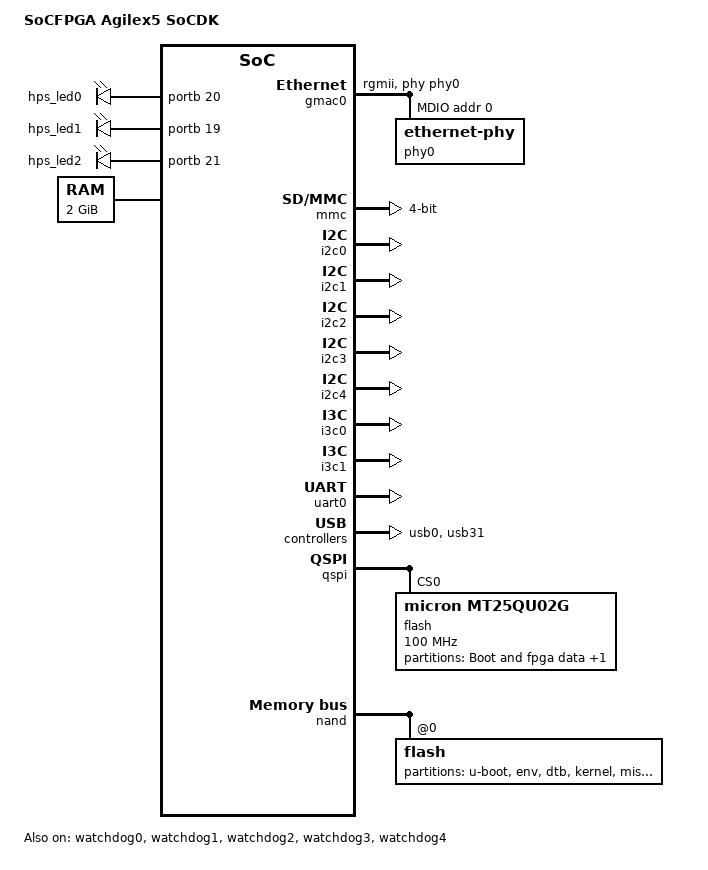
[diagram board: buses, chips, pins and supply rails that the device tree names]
// SPDX-License-Identifier:     GPL-2.0
/*
 * Copyright (C) 2023, Intel Corporation
 */
#include "socfpga_agilex5.dtsi"

/ {
	model = "SoCFPGA Agilex5 SoCDK";
	compatible = "intel,socfpga-agilex5-socdk", "intel,socfpga-agilex";

	aliases {
		serial0 = &uart0;
		ethernet0 = &gmac0;
	};

	chosen {
		stdout-path = "serial0:115200n8";
		bootargs = "console=uart8250,mmio32,0x10c02000,115200n8 \
			root=/dev/ram0 rw initrd=0x10000000 init=/sbin/init \
			ramdisk_size=10000000 earlycon=uart8250,mmio32,0x10c02000,115200n8 \
			panic=-1 nosmp rootfstype=ext3";
	};

	leds {
		compatible = "gpio-leds";
		hps0 {
			label = "hps_led0";
			gpios = <&portb 20 GPIO_ACTIVE_HIGH>;
		};

		hps1 {
			label = "hps_led1";
			gpios = <&portb 19 GPIO_ACTIVE_HIGH>;
		};

		hps2 {
			label = "hps_led2";
			gpios = <&portb 21 GPIO_ACTIVE_HIGH>;
		};
	};

	memory {
		device_type = "memory";
		reg = <0x0 0x80000000 0x0 0x80000000>;
		#address-cells = <0x2>;
		#size-cells = <0x2>;
		u-boot,dm-pre-reloc;
	};
};

&gpio1 {
	status = "okay";
};

&gmac0 {
	status = "okay";
	phy-mode = "rgmii";
	phy-handle = <&phy0>;

	max-frame-size = <9000>;

	mdio0 {
		#address-cells = <1>;
		#size-cells = <0>;
		compatible = "snps,dwmac-mdio";
		phy0: ethernet-phy@0 {
			reg = <0>;
		};
	};
};

&mmc {
	status = "okay";
	bus-width = <4>;
	sd-uhs-sdr50;
	sdhci-caps = <0x00000000 0x0000c800>;
	sdhci-caps-mask = <0x00002000 0x0000ff00>;
	no-sdio;
	cdns,phy-use-ext-lpbk-dqs = <1>;
	cdns,phy-use-lpbk-dqs = <1>;
	cdns,phy-use-phony-dqs = <1>;
	cdns,phy-use-phony-dqs-cmd = <1>;
	cdns,phy-io-mask-always-on = <0>;
	cdns,phy-io-mask-end = <5>;
	cdns,phy-io-mask-start = <0>;
	cdns,phy-data-select-oe-end = <1>;
	cdns,phy-sync-method = <1>;
	cdns,phy-sw-half-cycle-shift = <0>;
	cdns,phy-rd-del-sel = <52>;
	cdns,phy-underrun-suppress = <1>;
	cdns,phy-gate-cfg-always-on = <1>;
	cdns,phy-param-dll-bypass-mode = <1>;
	cdns,phy-param-phase-detect-sel = <2>;
	cdns,phy-param-dll-start-point = <254>;
	cdns,phy-read-dqs-cmd-delay = <0>;
	cdns,phy-clk-wrdqs-delay = <0>;
	cdns,phy-clk-wr-delay = <0>;
	cdns,phy-read-dqs-delay = <0>;
	cdns,phy-phony-dqs-timing = <0>;
	cdns,hrs09-rddata-en = <1>;
	cdns,hrs09-rdcmd-en = <1>;
	cdns,hrs09-extended-wr-mode = <1>;
	cdns,hrs09-extended-rd-mode = <1>;
	cdns,hrs10-hcsdclkadj = <3>;
	cdns,hrs16-wrdata1-sdclk-dly = <0>;
	cdns,hrs16-wrdata0-sdclk-dly = <0>;
	cdns,hrs16-wrcmd1-sdclk-dly = <0>;
	cdns,hrs16-wrcmd0-sdclk-dly = <0>;
	cdns,hrs16-wrdata1-dly = <0>;
	cdns,hrs16-wrdata0-dly = <0>;
	cdns,hrs16-wrcmd1-dly = <0>;
	cdns,hrs16-wrcmd0-dly = <0>;
	cdns,hrs07-rw-compensate = <10>;
	cdns,hrs07-idelay-val = <0>;
};

&i2c0 {
	status = "okay";
};

&i2c1 {
	status = "okay";
};

&i2c2 {
	status = "okay";
};

&i2c3 {
	status = "okay";
};

&i2c4 {
	status = "okay";
};

&i3c0 {
	status = "okay";
};

&i3c1 {
	status = "okay";
};

&osc1 {
	clock-frequency = <25000000>;
};

&uart0 {
	status = "okay";
};

&usb0 {
	status = "okay";
	disable-over-current;
};

&usb31 {
	status = "okay";
};

&watchdog0 {
	status = "okay";
};
&watchdog1 {
	status = "okay";
};
&watchdog2 {
	status = "okay";
};
&watchdog3 {
	status = "okay";
};
&watchdog4 {
	status = "okay";
};

&qspi {
	status = "okay";
	flash@0 {
		#address-cells = <1>;
		#size-cells = <1>;
		compatible = "micron,mt25qu02g", "jedec,spi-nor";
		reg = <0>;
		spi-max-frequency = <100000000>;

		m25p,fast-read;
		cdns,page-size = <256>;
		cdns,block-size = <16>;
		cdns,read-delay = <2>;
		cdns,tshsl-ns = <50>;
		cdns,tsd2d-ns = <50>;
		cdns,tchsh-ns = <4>;
		cdns,tslch-ns = <4>;

		partitions {
			compatible = "fixed-partitions";
			#address-cells = <1>;
			#size-cells = <1>;

			qspi_boot: partition@0 {
				label = "Boot and fpga data";
				reg = <0x0 0x03FE0000>;
			};

			qspi_rootfs: partition@3FE0000 {
				label = "Root Filesystem - JFFS2";
				reg = <0x03FE0000 0x0C020000>;
			};
		};
	};
};

&nand {
	status = "okay";

	flash@0 {
		#address-cells = <1>;
		#size-cells = <1>;
		reg = <0>;
		nand-bus-width = <16>;

		partition@0 {
			label = "u-boot";
			reg = <0 0x200000>;
		};
		partition@200000 {
			label = "env";
			reg = <0x200000 0x40000>;
		};
		partition@240000 {
			label = "dtb";
			reg = <0x240000 0x40000>;
		};
		partition@280000 {
			label = "kernel";
			reg = <0x280000 0x2000000>;
		};
		partition@2280000 {
			label = "misc";
			reg = <0x2280000 0x2000000>;
		};
		partition@4280000 {
			label = "rootfs";
			reg = <0x4280000 0x3d80000>;
		};
	};
};
